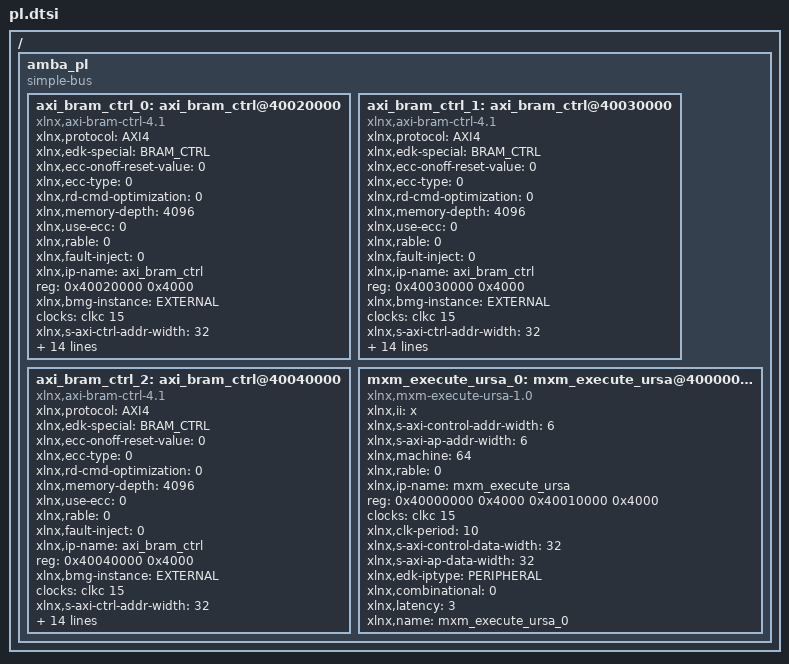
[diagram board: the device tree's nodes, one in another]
/ {
	amba_pl: amba_pl {
		ranges;
		compatible = "simple-bus";
		#address-cells = <1>;
		#size-cells = <1>;
		axi_bram_ctrl_0: axi_bram_ctrl@40020000 {
			xlnx,protocol = "AXI4";
			xlnx,edk-special = "BRAM_CTRL";
			compatible = "xlnx,axi-bram-ctrl-4.1";
			xlnx,ecc-onoff-reset-value = <0>;
			xlnx,ecc-type = <0>;
			xlnx,rd-cmd-optimization = <0>;
			xlnx,memory-depth = <4096>;
			xlnx,use-ecc = <0>;
			xlnx,rable = <0>;
			xlnx,fault-inject = <0>;
			xlnx,ip-name = "axi_bram_ctrl";
			reg = <0x40020000 0x4000>;
			xlnx,bmg-instance = "EXTERNAL";
			clocks = <&clkc 15>;
			xlnx,s-axi-ctrl-addr-width = <32>;
			xlnx,read-latency = <1>;
			xlnx,s-axi-supports-narrow-burst = <0>;
			xlnx,id-width = <13>;
			xlnx,supports-narrow-burst = <0>;
			xlnx,single-port-bram = <1>;
			xlnx,ecc = <0>;
			xlnx,edk-iptype = "PERIPHERAL";
			status = "okay";
			clock-names = "s_axi_aclk";
			xlnx,bram-addr-width = <12>;
			xlnx,bram-inst-mode = "EXTERNAL";
			xlnx,data-width = <32>;
			xlnx,s-axi-ctrl-data-width = <32>;
			xlnx,s-axi-id-width = <13>;
			xlnx,mem-depth = <4096>;
			xlnx,name = "axi_bram_ctrl_0";
		};
		axi_bram_ctrl_1: axi_bram_ctrl@40030000 {
			xlnx,protocol = "AXI4";
			xlnx,edk-special = "BRAM_CTRL";
			compatible = "xlnx,axi-bram-ctrl-4.1";
			xlnx,ecc-onoff-reset-value = <0>;
			xlnx,ecc-type = <0>;
			xlnx,rd-cmd-optimization = <0>;
			xlnx,memory-depth = <4096>;
			xlnx,use-ecc = <0>;
			xlnx,rable = <0>;
			xlnx,fault-inject = <0>;
			xlnx,ip-name = "axi_bram_ctrl";
			reg = <0x40030000 0x4000>;
			xlnx,bmg-instance = "EXTERNAL";
			clocks = <&clkc 15>;
			xlnx,s-axi-ctrl-addr-width = <32>;
			xlnx,read-latency = <1>;
			xlnx,s-axi-supports-narrow-burst = <0>;
			xlnx,id-width = <13>;
			xlnx,supports-narrow-burst = <0>;
			xlnx,single-port-bram = <1>;
			xlnx,ecc = <0>;
			xlnx,edk-iptype = "PERIPHERAL";
			status = "okay";
			clock-names = "s_axi_aclk";
			xlnx,bram-addr-width = <12>;
			xlnx,bram-inst-mode = "EXTERNAL";
			xlnx,data-width = <32>;
			xlnx,s-axi-ctrl-data-width = <32>;
			xlnx,s-axi-id-width = <13>;
			xlnx,mem-depth = <4096>;
			xlnx,name = "axi_bram_ctrl_1";
		};
		axi_bram_ctrl_2: axi_bram_ctrl@40040000 {
			xlnx,protocol = "AXI4";
			xlnx,edk-special = "BRAM_CTRL";
			compatible = "xlnx,axi-bram-ctrl-4.1";
			xlnx,ecc-onoff-reset-value = <0>;
			xlnx,ecc-type = <0>;
			xlnx,rd-cmd-optimization = <0>;
			xlnx,memory-depth = <4096>;
			xlnx,use-ecc = <0>;
			xlnx,rable = <0>;
			xlnx,fault-inject = <0>;
			xlnx,ip-name = "axi_bram_ctrl";
			reg = <0x40040000 0x4000>;
			xlnx,bmg-instance = "EXTERNAL";
			clocks = <&clkc 15>;
			xlnx,s-axi-ctrl-addr-width = <32>;
			xlnx,read-latency = <1>;
			xlnx,s-axi-supports-narrow-burst = <0>;
			xlnx,id-width = <13>;
			xlnx,supports-narrow-burst = <0>;
			xlnx,single-port-bram = <1>;
			xlnx,ecc = <0>;
			xlnx,edk-iptype = "PERIPHERAL";
			status = "okay";
			clock-names = "s_axi_aclk";
			xlnx,bram-addr-width = <12>;
			xlnx,bram-inst-mode = "EXTERNAL";
			xlnx,data-width = <32>;
			xlnx,s-axi-ctrl-data-width = <32>;
			xlnx,s-axi-id-width = <13>;
			xlnx,mem-depth = <4096>;
			xlnx,name = "axi_bram_ctrl_2";
		};
		mxm_execute_ursa_0: mxm_execute_ursa@40000000 {
			compatible = "xlnx,mxm-execute-ursa-1.0";
			xlnx,ii = "x";
			xlnx,s-axi-control-addr-width = <6>;
			xlnx,s-axi-ap-addr-width = <6>;
			xlnx,machine = <64>;
			xlnx,rable = <0>;
			xlnx,ip-name = "mxm_execute_ursa";
			reg = <0x40000000 0x4000 0x40010000 0x4000>;
			clocks = <&clkc 15>;
			xlnx,clk-period = <10>;
			xlnx,s-axi-control-data-width = <32>;
			xlnx,s-axi-ap-data-width = <32>;
			xlnx,edk-iptype = "PERIPHERAL";
			status = "okay";
			clock-names = "ap_clk";
			xlnx,combinational = <0>;
			xlnx,latency = <3>;
			xlnx,name = "mxm_execute_ursa_0";
		};
	};
};
